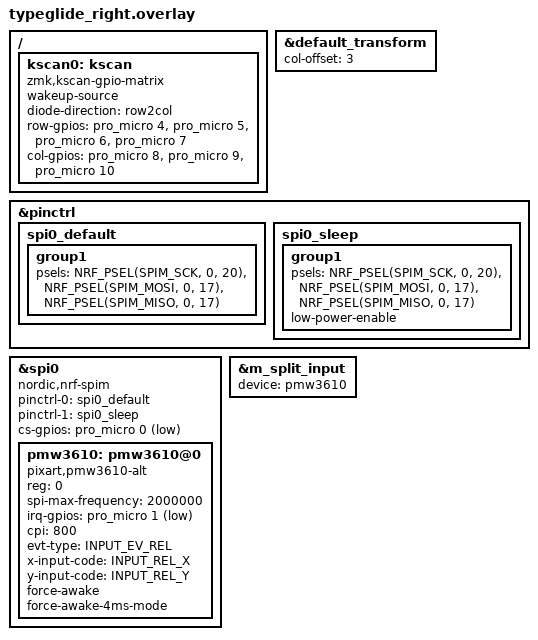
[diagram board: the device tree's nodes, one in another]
#include "typeglide.dtsi"
#include <dt-bindings/gpio/gpio.h>
#include "joystick.dtsi"

// Right half — mirrored physically but same GPIO structure
// col 0 = index (innermost), col 1 = middle, col 2 = ring (outermost)
// ZMK split driver offsets these to global cols 3-5 automatically.
// row 3 col 0 = thumb, row 3 col 2 = pinky, row 3 col 1 = spare (no key)
// TODO: adjust pin numbers to match your PCB routing

&default_transform {
    col-offset = <3>;
};


/ {
    kscan0: kscan {
        compatible = "zmk,kscan-gpio-matrix";
        wakeup-source;
        diode-direction = "row2col";

        row-gpios
            = <&pro_micro 4 GPIO_ACTIVE_HIGH>  // row 0 (top)
            , <&pro_micro 5 GPIO_ACTIVE_HIGH>  // row 1
            , <&pro_micro 6 GPIO_ACTIVE_HIGH>  // row 2
            , <&pro_micro 7 GPIO_ACTIVE_HIGH>  // row 3 (thumb + pinky)
            ;

        col-gpios
            = <&pro_micro 8  (GPIO_ACTIVE_HIGH | GPIO_PULL_DOWN)>  // col 0 — index
            , <&pro_micro 9  (GPIO_ACTIVE_HIGH | GPIO_PULL_DOWN)>  // col 1 — middle
            , <&pro_micro 10 (GPIO_ACTIVE_HIGH | GPIO_PULL_DOWN)>  // col 2 — ring
            ;
    };
};


&pinctrl {
    spi0_default: spi0_default {
        group1 {
            psels = <NRF_PSEL(SPIM_SCK, 0, 20)>,
                <NRF_PSEL(SPIM_MOSI, 0, 17)>,
                <NRF_PSEL(SPIM_MISO, 0, 17)>;
        };
    };

    spi0_sleep: spi0_sleep {
        group1 {
            psels = <NRF_PSEL(SPIM_SCK, 0, 20)>,
                <NRF_PSEL(SPIM_MOSI, 0, 17)>,
                <NRF_PSEL(SPIM_MISO, 0, 17)>;
            low-power-enable;
        };
    };
};

#include <zephyr/dt-bindings/input/input-event-codes.h>


&spi0 {
    status = "okay";
    compatible = "nordic,nrf-spim";
    pinctrl-0 = <&spi0_default>;
    pinctrl-1 = <&spi0_sleep>;
    pinctrl-names = "default", "sleep";
    cs-gpios = <&pro_micro 0 GPIO_ACTIVE_LOW>;

    pmw3610: pmw3610@0 {
        status = "okay";
        compatible = "pixart,pmw3610-alt";
        reg = <0>;
        spi-max-frequency = <2000000>;
        irq-gpios = <&pro_micro 1 (GPIO_ACTIVE_LOW  | GPIO_PULL_UP)>;
        cpi = <800>;
        evt-type = <INPUT_EV_REL>;
        x-input-code = <INPUT_REL_X>;
        y-input-code = <INPUT_REL_Y>;

       force-awake;
       force-awake-4ms-mode;
    };
};


&m_split_input {
    device = <&pmw3610>;
};

/*

&right_joystick_split {
    device = <&joystick>;
};
*/
/*

/ {
    joystick_debug_listener {
        compatible = "zmk,input-listener";
        device = <&joystick>;
    };
};
*/
